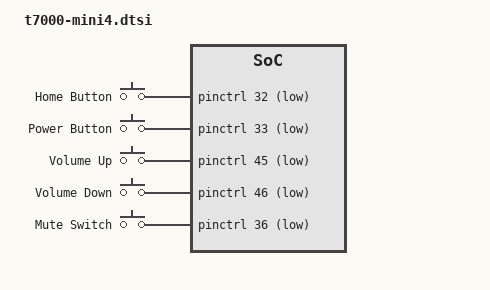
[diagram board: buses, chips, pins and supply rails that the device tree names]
// SPDX-License-Identifier: GPL-2.0+ OR MIT
/*
 * Apple iPad mini 4 common device tree
 *
 * Copyright (c) 2022, Konrad Dybcio <konradybcio@kernel.org>
 */

#include "t7000.dtsi"
#include "t7000-common.dtsi"
#include "t7000-handheld.dtsi"
#include <dt-bindings/input/input.h>

/ {
	chassis-type = "tablet";

	gpio-keys {
		compatible = "gpio-keys";

		button-home {
			label = "Home Button";
			gpios = <&pinctrl 32 GPIO_ACTIVE_LOW>;
			linux,code = <KEY_HOMEPAGE>;
			wakeup-source;
		};

		button-power {
			label = "Power Button";
			gpios = <&pinctrl 33 GPIO_ACTIVE_LOW>;
			linux,code = <KEY_POWER>;
			wakeup-source;
		};

		button-volup {
			label = "Volume Up";
			gpios = <&pinctrl 45 GPIO_ACTIVE_LOW>;
			linux,code = <KEY_VOLUMEUP>;
		};

		button-voldown {
			label = "Volume Down";
			gpios = <&pinctrl 46 GPIO_ACTIVE_LOW>;
			linux,code = <KEY_VOLUMEDOWN>;
		};

		switch-mute {
			label = "Mute Switch";
			gpios = <&pinctrl 36 GPIO_ACTIVE_LOW>;
			linux,code = <KEY_MUTE>;
		};
	};
};

&framebuffer0 {
	power-domains = <&ps_disp0 &ps_dp>;
};

&typhoon_opp06 {
	status = "okay";
};

&typhoon_opp07 {
	status = "okay";
};
